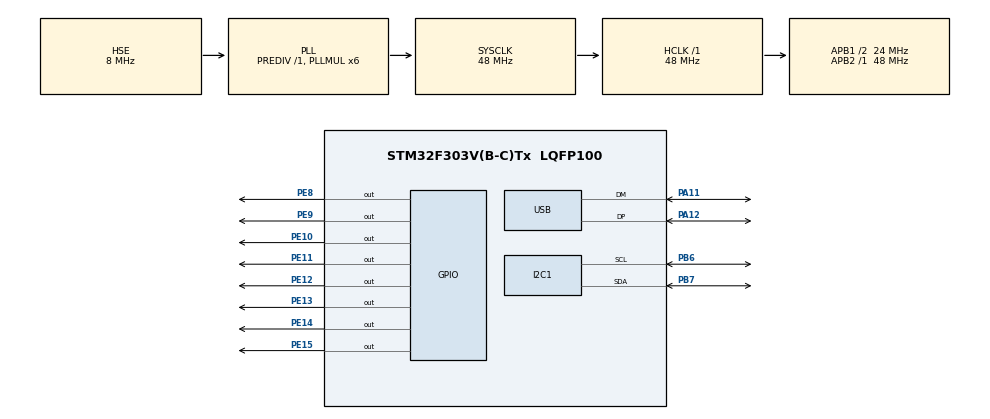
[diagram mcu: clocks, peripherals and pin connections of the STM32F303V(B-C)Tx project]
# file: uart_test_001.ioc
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Mcu.Family=STM32F3
Mcu.Name=STM32F303V(B-C)Tx
Mcu.Package=LQFP100
NVIC.PriorityGroup=NVIC_PRIORITYGROUP_4
NVIC.USB_HP_IRQn=true\:0\:0\:false\:false\:true\:true\:true
NVIC.USB_LP_IRQn=true\:0\:0\:false\:false\:true\:true\:true
PA11.Mode=Device
PA11.Signal=USB_DM
PA12.Mode=Device
PA12.Signal=USB_DP
PB6.Mode=I2C
PB6.Signal=I2C1_SCL
PB7.Mode=I2C
PB7.Signal=I2C1_SDA
PE10.Signal=GPIO_Output
PE11.Signal=GPIO_Output
PE12.Signal=GPIO_Output
PE13.Signal=GPIO_Output
PE14.Signal=GPIO_Output
PE15.Signal=GPIO_Output
PE8.Signal=GPIO_Output
PE9.Signal=GPIO_Output
PF0-OSC_IN.Mode=HSE-External-Clock-Source
PF0-OSC_IN.Signal=RCC_OSC_IN
ProjectManager.HeapSize=0x200
ProjectManager.StackSize=0x400
ProjectManager.TargetToolchain=MDK-ARM V5.27
RCC.AHBFreq_Value=48000000
RCC.APB1CLKDivider=RCC_HCLK_DIV2
RCC.APB1Freq_Value=24000000
RCC.APB1TimFreq_Value=48000000
RCC.APB2Freq_Value=48000000
RCC.APB2TimFreq_Value=48000000
RCC.CortexFreq_Value=48000000
RCC.HCLKFreq_Value=48000000
RCC.HSE_VALUE=8000000
RCC.HSI_VALUE=8000000
RCC.LSE_VALUE=32768
RCC.PLLMUL=RCC_PLL_MUL6
RCC.SYSCLKFreq_VALUE=48000000
RCC.SYSCLKSourceVirtual=RCC_SYSCLKSOURCE_PLLCLK
RCC.USBFreq_Value=48000000
USB_DEVICE.CLASS_NAME_FS=CDC
USB_DEVICE.VirtualMode=Cdc
USB_DEVICE.VirtualModeFS=Cdc_FS
VP_USB_DEVICE_VS_USB_DEVICE_CDC_FS.Mode=CDC_FS
board=custom

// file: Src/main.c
/* USER CODE BEGIN Header */
/**
  ******************************************************************************
  * @file           : main.c
  * @brief          : Main program body
  ******************************************************************************
  * @attention
  *
  * <h2><center>&copy; Copyright (c) 2020 STMicroelectronics.
  * All rights reserved.</center></h2>
  *
  * This software component is licensed by ST under BSD 3-Clause license,
  * the "License"; You may not use this file except in compliance with the
  * License. You may obtain a copy of the License at:
  *                        opensource.org/licenses/BSD-3-Clause
  *
  ******************************************************************************
  */
/* USER CODE END Header */

#include "main.h"
#include "usb_device.h"

/* USER CODE BEGIN Includes */
#include "i2c_cdc.h"
/* USER CODE END Includes */

I2C_HandleTypeDef hi2c1;

void SystemClock_Config(void);
static void MX_GPIO_Init(void);
static void MX_I2C1_Init(void);
/* USER CODE BEGIN PFP */
void clear_sprintf(char *buf, uint8_t len);
/* USER CODE END PFP */

/* USER CODE BEGIN 0 */
uint8_t cdcRxDataBuf[255] = {0};
uint8_t cdc_flag = 0;

uint8_t devAddr = 0;
uint8_t regAddr = 0;
uint8_t cntByte = 0;

uint8_t i2cTxDataBuf[255] = {0};

char foutBuf[64] = {' '};
char *ptr;

/* USER CODE END 0 */

int main(void)
{

  /* MCU Configuration--------------------------------------------------------*/

  /* Reset of all peripherals, Initializes the Flash interface and the Systick. */
  HAL_Init();

  /* Configure the system clock */
  SystemClock_Config();

  /* Initialize all configured peripherals */
  MX_GPIO_Init();
  MX_USB_DEVICE_Init();
  MX_I2C1_Init();

  /* Infinite loop */
  /* USER CODE BEGIN WHILE */
  while (1)
  {
		if(cdc_flag == 1){
			cdc_i2c_run(cdcRxDataBuf);
			cdc_flag = 0;
		}
    /* USER CODE END WHILE */

  }
}

void SystemClock_Config(void)
{
  RCC_OscInitTypeDef RCC_OscInitStruct = {0};
  RCC_ClkInitTypeDef RCC_ClkInitStruct = {0};
  RCC_PeriphCLKInitTypeDef PeriphClkInit = {0};

  /** Initializes the CPU, AHB and APB busses clocks
  */
  RCC_OscInitStruct.OscillatorType = RCC_OSCILLATORTYPE_HSI|RCC_OSCILLATORTYPE_HSE;
  RCC_OscInitStruct.HSEState = RCC_HSE_BYPASS;
  RCC_OscInitStruct.HSEPredivValue = RCC_HSE_PREDIV_DIV1;
  RCC_OscInitStruct.HSIState = RCC_HSI_ON;
  RCC_OscInitStruct.HSICalibrationValue = RCC_HSICALIBRATION_DEFAULT;
  RCC_OscInitStruct.PLL.PLLState = RCC_PLL_ON;
  RCC_OscInitStruct.PLL.PLLSource = RCC_PLLSOURCE_HSE;
  RCC_OscInitStruct.PLL.PLLMUL = RCC_PLL_MUL6;
  if (HAL_RCC_OscConfig(&RCC_OscInitStruct) != HAL_OK)
  {
    Error_Handler();
  }
  /** Initializes the CPU, AHB and APB busses clocks
  */
  RCC_ClkInitStruct.ClockType = RCC_CLOCKTYPE_HCLK|RCC_CLOCKTYPE_SYSCLK
                              |RCC_CLOCKTYPE_PCLK1|RCC_CLOCKTYPE_PCLK2;
  RCC_ClkInitStruct.SYSCLKSource = RCC_SYSCLKSOURCE_PLLCLK;
  RCC_ClkInitStruct.AHBCLKDivider = RCC_SYSCLK_DIV1;
  RCC_ClkInitStruct.APB1CLKDivider = RCC_HCLK_DIV2;
  RCC_ClkInitStruct.APB2CLKDivider = RCC_HCLK_DIV1;

  if (HAL_RCC_ClockConfig(&RCC_ClkInitStruct, FLASH_LATENCY_1) != HAL_OK)
  {
    Error_Handler();
  }
  PeriphClkInit.PeriphClockSelection = RCC_PERIPHCLK_USB|RCC_PERIPHCLK_I2C1;
  PeriphClkInit.I2c1ClockSelection = RCC_I2C1CLKSOURCE_HSI;
  PeriphClkInit.USBClockSelection = RCC_USBCLKSOURCE_PLL;
  if (HAL_RCCEx_PeriphCLKConfig(&PeriphClkInit) != HAL_OK)
  {
    Error_Handler();
  }
}

static void MX_I2C1_Init(void)
{

  hi2c1.Instance = I2C1;
  hi2c1.Init.Timing = 0x2000090E;
  hi2c1.Init.OwnAddress1 = 0;
  hi2c1.Init.AddressingMode = I2C_ADDRESSINGMODE_7BIT;
  hi2c1.Init.DualAddressMode = I2C_DUALADDRESS_DISABLE;
  hi2c1.Init.OwnAddress2 = 0;
  hi2c1.Init.OwnAddress2Masks = I2C_OA2_NOMASK;
  hi2c1.Init.GeneralCallMode = I2C_GENERALCALL_DISABLE;
  hi2c1.Init.NoStretchMode = I2C_NOSTRETCH_DISABLE;
  if (HAL_I2C_Init(&hi2c1) != HAL_OK)
  {
    Error_Handler();
  }
  /** Configure Analogue filter
  */
  if (HAL_I2CEx_ConfigAnalogFilter(&hi2c1, I2C_ANALOGFILTER_ENABLE) != HAL_OK)
  {
    Error_Handler();
  }
  /** Configure Digital filter
  */
  if (HAL_I2CEx_ConfigDigitalFilter(&hi2c1, 0) != HAL_OK)
  {
    Error_Handler();
  }

}

static void MX_GPIO_Init(void)
{
  GPIO_InitTypeDef GPIO_InitStruct = {0};

  /* GPIO Ports Clock Enable */
  __HAL_RCC_GPIOF_CLK_ENABLE();
  __HAL_RCC_GPIOE_CLK_ENABLE();
  __HAL_RCC_GPIOA_CLK_ENABLE();
  __HAL_RCC_GPIOB_CLK_ENABLE();

  /*Configure GPIO pin Output Level */
  HAL_GPIO_WritePin(GPIOE, GPIO_PIN_8|GPIO_PIN_9|GPIO_PIN_10|GPIO_PIN_11
                          |GPIO_PIN_12|GPIO_PIN_13|GPIO_PIN_14|GPIO_PIN_15, GPIO_PIN_RESET);

  /*Configure GPIO pins : PE8 PE9 PE10 PE11
                           PE12 PE13 PE14 PE15 */
  GPIO_InitStruct.Pin = GPIO_PIN_8|GPIO_PIN_9|GPIO_PIN_10|GPIO_PIN_11
                          |GPIO_PIN_12|GPIO_PIN_13|GPIO_PIN_14|GPIO_PIN_15;
  GPIO_InitStruct.Mode = GPIO_MODE_OUTPUT_PP;
  GPIO_InitStruct.Pull = GPIO_NOPULL;
  GPIO_InitStruct.Speed = GPIO_SPEED_FREQ_LOW;
  HAL_GPIO_Init(GPIOE, &GPIO_InitStruct);

}

void Error_Handler(void)
{
}

/************************ (C) COPYRIGHT STMicroelectronics *****END OF FILE****/
